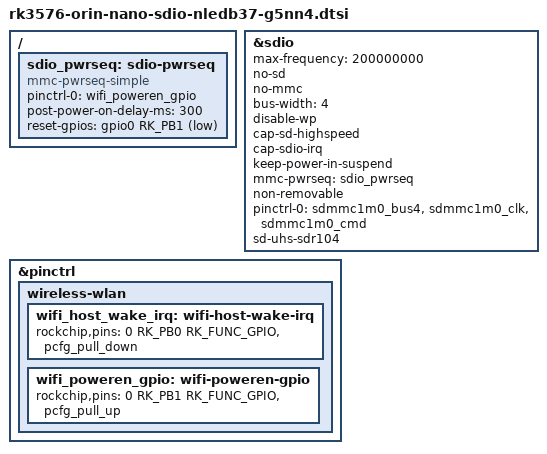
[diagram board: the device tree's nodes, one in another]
// SPDX-License-Identifier: (GPL-2.0+ OR MIT)
/*
 * Guangzhou Easy EAI Technology Co., Ltd.
 *
 */

/ {
	
	sdio_pwrseq: sdio-pwrseq {
		compatible = "mmc-pwrseq-simple";
		pinctrl-names = "default";
		pinctrl-0 = <&wifi_poweren_gpio>;

		/*
		 * On the module itself this is one of these (depending
		 * on the actual card populated):
		 * - SDIO_RESET_L_WL_REG_ON
		 * - PDN (power down when low)
		 */
		post-power-on-delay-ms = <300>;
		reset-gpios = <&gpio0 RK_PB1 GPIO_ACTIVE_LOW>;
	};
};

&sdio {
	max-frequency = <200000000>;
	no-sd;
	no-mmc;
	bus-width = <4>;
	disable-wp;
	cap-sd-highspeed;
	cap-sdio-irq;
	keep-power-in-suspend;
	mmc-pwrseq = <&sdio_pwrseq>;
	non-removable;
	//sd-uhs-sdr104;
	pinctrl-names = "default";
	pinctrl-0 = <&sdmmc1m0_bus4 &sdmmc1m0_clk &sdmmc1m0_cmd>;
	sd-uhs-sdr104;
	status = "okay";
};

&pinctrl {
	wireless-wlan {
		wifi_host_wake_irq: wifi-host-wake-irq {
			rockchip,pins = <0 RK_PB0 RK_FUNC_GPIO &pcfg_pull_down>;
		};

		wifi_poweren_gpio: wifi-poweren-gpio {
			rockchip,pins = <0 RK_PB1 RK_FUNC_GPIO &pcfg_pull_up>;
		};
	};
};

